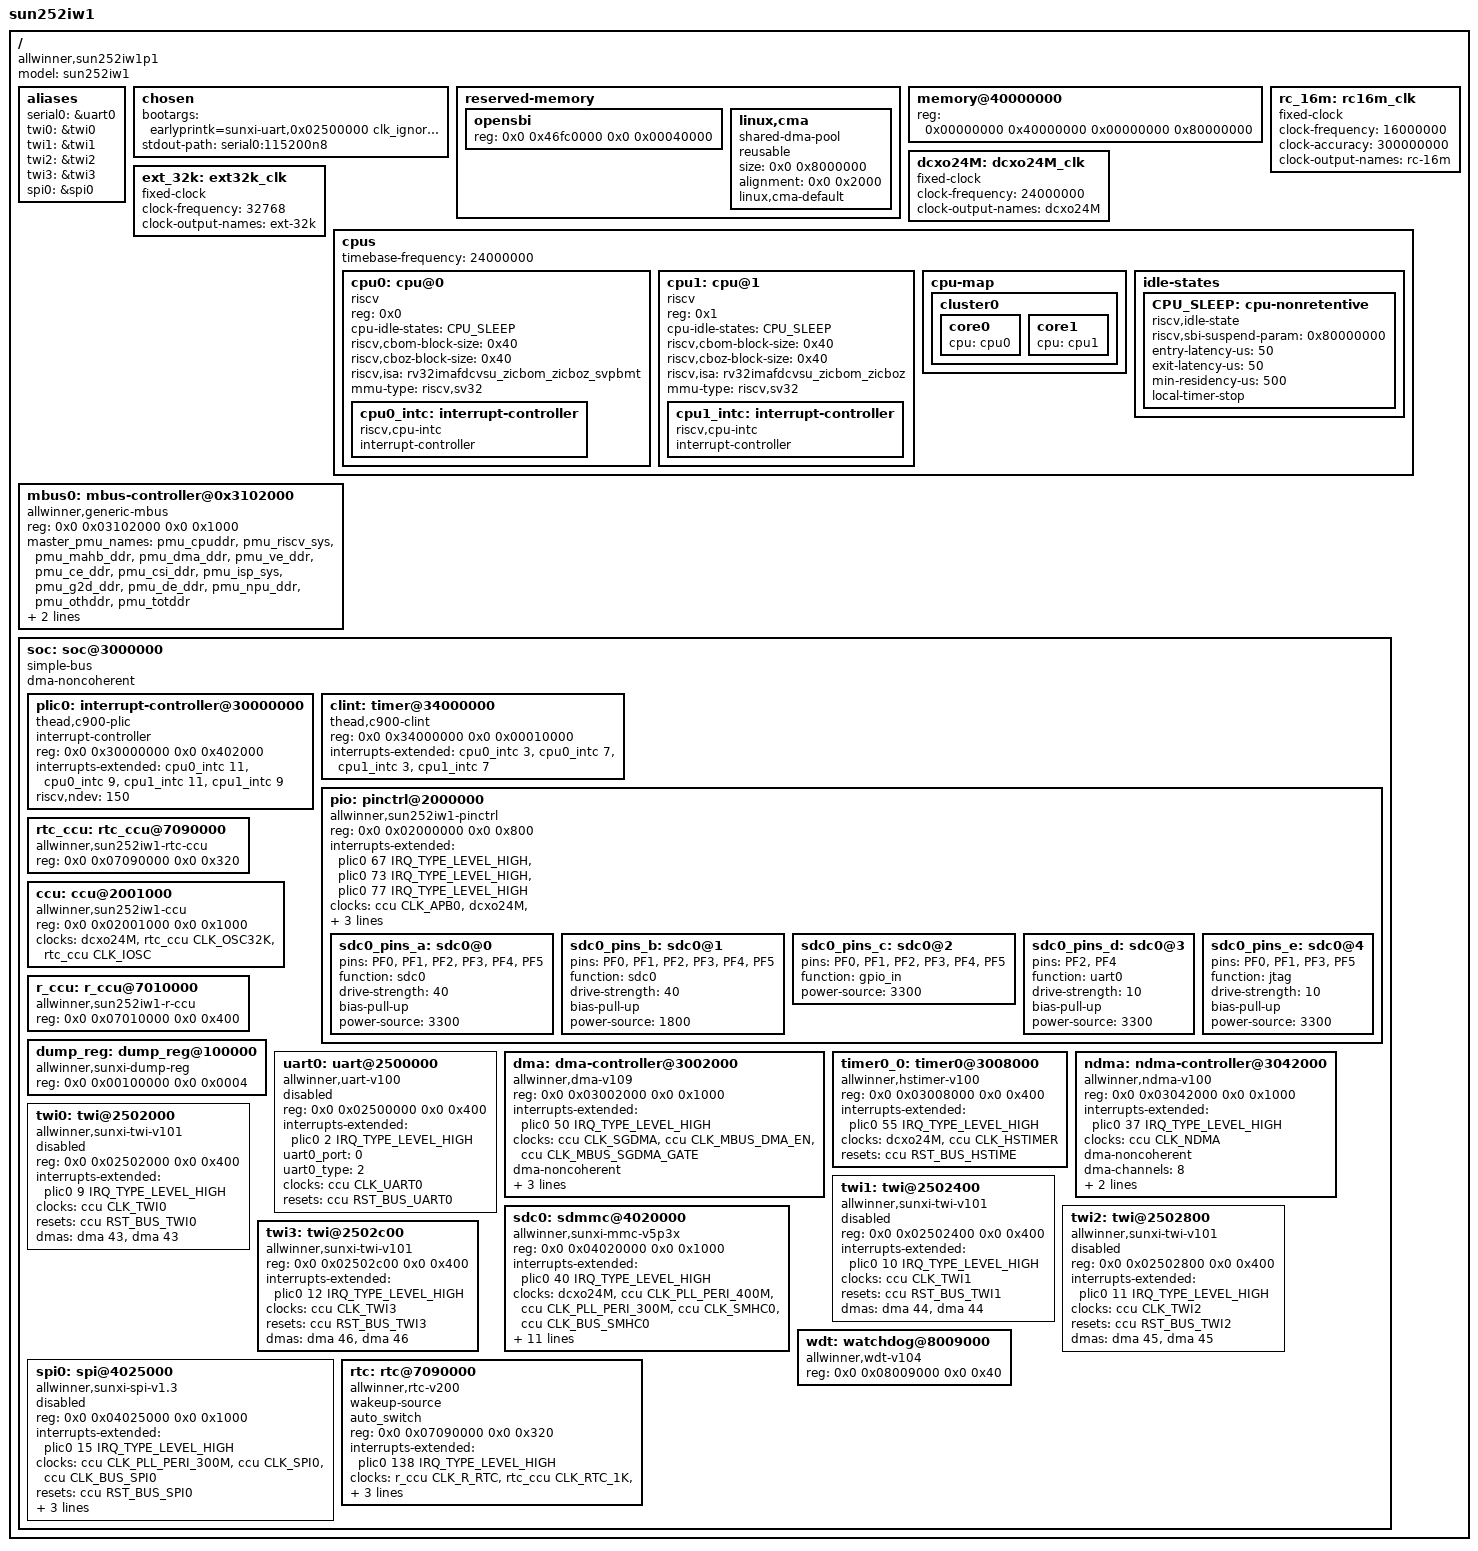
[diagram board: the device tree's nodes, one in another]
// SPDX-License-Identifier: (GPL-2.0+ or MIT)
#include <dt-bindings/clock/sun252iw1-ccu.h>
#include <dt-bindings/clock/sun252iw1-r-ccu.h>
#include <dt-bindings/clock/sun252iw1-rtc.h>
#include <dt-bindings/reset/sun252iw1-ccu.h>
#include <dt-bindings/reset/sun252iw1-r-ccu.h>
#include <dt-bindings/gpio/gpio.h>
#include <dt-bindings/gpio/sun4i-gpio.h>
#include <dt-bindings/interrupt-controller/irq.h>
#include <dt-bindings/phy/phy.h>
#include <dt-bindings/thermal/thermal.h>
#include <dt-bindings/spi/sunxi-spi.h>

/ {
	model = "sun252iw1";
	compatible = "allwinner,sun252iw1p1";
	#address-cells = <2>;
	#size-cells = <2>;

	aliases {
		serial0 = &uart0;
		twi0 = &twi0;
		twi1 = &twi1;
		twi2 = &twi2;
		twi3 = &twi3;
		spi0 = &spi0;
	};

	chosen {
		bootargs = "earlyprintk=sunxi-uart,0x02500000 clk_ignore_unused initcall_debug=0 console=ttyAS0,115200 loglevel=8 root=/dev/mmcblk0p5 init=/init partitions=boot-resource@mmcblk0p1:env@mmcblk0p2:env-redund@mmcblk0p3:boot@mmcblk0p4:rootfs@mmcblk0p5:private@mmcblk0p6:rootfs_data@mmcblk0p7:UDISK@mmcblk0p8 specialstr= gpt=1 mbr_offset=1556480";
		stdout-path = "serial0:115200n8";  /* opensbi needs this */
	};

	reserved-memory {
		#address-cells = <2>;
		#size-cells = <2>;
		ranges;
		opensbi {
			reg = <0x0 0x46fc0000 0x0 0x00040000>;
		};

		linux,cma {
			compatible = "shared-dma-pool";
			reusable;
			size = <0x0 0x8000000>;
			alignment = <0x0 0x2000>;
			linux,cma-default;
		};
	};

	/* avoid panic when memory-node err(from uboot) */
	memory@40000000 {
		device_type = "memory";
		reg = <0x00000000 0x40000000 0x00000000 0x80000000>;
	};

	dcxo24M: dcxo24M_clk {
		#clock-cells = <0>;
		compatible = "fixed-clock";
		clock-frequency = <24000000>;
		clock-output-names = "dcxo24M";
	};

	rc_16m: rc16m_clk {
		#clock-cells = <0>;
		compatible = "fixed-clock";
		clock-frequency = <16000000>;
		clock-accuracy = <300000000>;
		clock-output-names = "rc-16m";
	};

	ext_32k: ext32k_clk {
		#clock-cells = <0>;
		compatible = "fixed-clock";
		clock-frequency = <32768>;
		clock-output-names = "ext-32k";
	};
	cpus {
		#address-cells = <1>;
		#size-cells = <0>;
		timebase-frequency = <24000000>;

		cpu0: cpu@0 {
			device_type = "cpu";
			reg = <0x0>;
			status = "okay";
			compatible = "riscv";
			cpu-idle-states = <&CPU_SLEEP>;
			riscv,cbom-block-size = <0x40>;
			riscv,cboz-block-size = <0x40>;
			riscv,isa = "rv32imafdcvsu_zicbom_zicboz_svpbmt";
			mmu-type = "riscv,sv32";
			cpu0_intc: interrupt-controller {
				#address-cells = <0>;
				#interrupt-cells = <1>;
				compatible = "riscv,cpu-intc";
				interrupt-controller;
			};
		};

		cpu1: cpu@1 {
			device_type = "cpu";
			reg = <0x1>;
			status = "okay";
			compatible = "riscv";
			cpu-idle-states = <&CPU_SLEEP>;
			riscv,cbom-block-size = <0x40>;
			riscv,cboz-block-size = <0x40>;
			riscv,isa = "rv32imafdcvsu_zicbom_zicboz";
			mmu-type = "riscv,sv32";
			cpu1_intc: interrupt-controller {
				#address-cells = <0>;
				#interrupt-cells = <1>;
				compatible = "riscv,cpu-intc";
				interrupt-controller;
			};
		};

		cpu-map {
			cluster0 {
				core0 {
					cpu = <&cpu0>;
				};
				core1 {
					cpu = <&cpu1>;
				};
			};
		};

		idle-states {
			CPU_SLEEP: cpu-nonretentive {
				compatible = "riscv,idle-state";
				riscv,sbi-suspend-param = <0x80000000>;
				entry-latency-us = <50>;
				exit-latency-us = <50>;
				min-residency-us = <500>;
				local-timer-stop;
			};
		};
	};

	mbus0: mbus-controller@0x3102000 {
		compatible = "allwinner,generic-mbus";
		reg = <0x0 0x03102000 0x0 0x1000>;
		#mbus-cells = <1>;
		status = "okay";
		master_pmu_names = "pmu_cpuddr", "pmu_riscv_sys", "pmu_mahb_ddr",
		"pmu_dma_ddr", "pmu_ve_ddr", "pmu_ce_ddr", "pmu_csi_ddr",
		"pmu_isp_sys", "pmu_g2d_ddr", "pmu_de_ddr", "pmu_npu_ddr",
		"pmu_othddr", "pmu_totddr";
		master_pmu_idxs =<0 1 2 3 4 6 7 8 9 10 13 14 15>;
		master_port_idxs = <0 39 2 3 4 40 11 12 13 16 38>;
	};

	soc: soc@3000000 {
		compatible = "simple-bus";
		#address-cells = <2>;
		#size-cells = <2>;
		ranges;
		dma-noncoherent;

		plic0: interrupt-controller@30000000 {
			compatible = "thead,c900-plic";
			#address-cells = <0>;
			#interrupt-cells = <2>;
			interrupt-controller;
			reg = <0x0 0x30000000 0x0 0x402000>;
			interrupts-extended = <&cpu0_intc 11 &cpu0_intc 9>,
					      <&cpu1_intc 11 &cpu1_intc 9>;
			riscv,ndev = <150>;
		};

		clint: timer@34000000 {
			compatible = "thead,c900-clint";
			reg = <0x0 0x34000000 0x0 0x00010000>;
			interrupts-extended = <&cpu0_intc 3>, <&cpu0_intc 7>,
					      <&cpu1_intc 3>, <&cpu1_intc 7>;
		};

		pio: pinctrl@2000000 {
			compatible = "allwinner,sun252iw1-pinctrl";
			reg = <0x0 0x02000000 0x0 0x800>;
			interrupts-extended = <&plic0 67 IRQ_TYPE_LEVEL_HIGH>,
				<&plic0 73 IRQ_TYPE_LEVEL_HIGH>,
				<&plic0 77 IRQ_TYPE_LEVEL_HIGH>;
			clocks = <&ccu CLK_APB0>, <&dcxo24M>, <&rtc_ccu CLK_OSC32K>;
			clock-names = "apb", "hosc", "losc";
			gpio-controller;
			#gpio-cells = <3>;
			interrupt-controller;
			#interrupt-cells = <3>;
			#address-cells = <2>;

			sdc0_pins_a: sdc0@0 {
				pins = "PF0", "PF1", "PF2",
						"PF3", "PF4", "PF5";
				function = "sdc0";
				drive-strength = <40>;
				bias-pull-up;
				power-source = <3300>;
			};

			sdc0_pins_b: sdc0@1 {
				pins = "PF0", "PF1", "PF2",
						"PF3", "PF4", "PF5";
				function = "sdc0";
				drive-strength = <40>;
				bias-pull-up;
				power-source = <1800>;
			};

			sdc0_pins_c: sdc0@2 {
				pins = "PF0", "PF1", "PF2",
						"PF3", "PF4", "PF5";
				function = "gpio_in";
				power-source = <3300>;
			};

			/* TODO: add jtag pin */
			sdc0_pins_d: sdc0@3 {
				pins = "PF2", "PF4";
				function = "uart0";
				drive-strength = <10>;
				bias-pull-up;
				power-source = <3300>;
			};

			sdc0_pins_e: sdc0@4 {
				pins = "PF0", "PF1", "PF3",
						"PF5";
				function = "jtag";
				drive-strength = <10>;
				bias-pull-up;
				power-source = <3300>;
			};
		};

		rtc_ccu: rtc_ccu@7090000 {
			compatible = "allwinner,sun252iw1-rtc-ccu";
			device_type = "rtc-ccu";
			reg = <0x0 0x07090000 0x0 0x320>;  /* The same as rtc */
			#clock-cells = <1>;
		};

		ccu: ccu@2001000 {
			compatible = "allwinner,sun252iw1-ccu";
			reg = <0x0 0x02001000 0x0 0x1000>;
			clocks = <&dcxo24M>, <&rtc_ccu CLK_OSC32K>, <&rtc_ccu CLK_IOSC>;
			clock-names = "hosc", "losc", "iosc";
			#clock-cells = <1>;
			#reset-cells = <1>;
		};

		r_ccu: r_ccu@7010000 {
			compatible = "allwinner,sun252iw1-r-ccu";
			reg = <0x0 0x07010000 0x0 0x400>;
			#clock-cells = <1>;
			#reset-cells = <1>;
		};

		dump_reg:dump_reg@100000 {
			compatible = "allwinner,sunxi-dump-reg";
			reg = <0x0 0x00100000 0x0 0x0004>;
		};

		uart0: uart@2500000 {
			compatible = "allwinner,uart-v100",
				     "allwinner,sunxi-uart";  /* opensbi needs this */
			reg = <0x0 0x02500000 0x0 0x400>;
			interrupts-extended = <&plic0 2 IRQ_TYPE_LEVEL_HIGH>;
			uart0_port = <0>;
			uart0_type = <2>;
			clocks = <&ccu CLK_UART0>;
			resets = <&ccu RST_BUS_UART0>;
			status = "disabled";
		};

		dma:dma-controller@3002000 {
			compatible = "allwinner,dma-v109";
			reg = <0x0 0x03002000 0x0 0x1000>;
			interrupts-extended = <&plic0 50 IRQ_TYPE_LEVEL_HIGH>;
			clocks = <&ccu CLK_SGDMA>, <&ccu CLK_MBUS_DMA_EN>, <&ccu CLK_MBUS_SGDMA_GATE>;
			clock-names = "bus", "mbus-en", "mbus";
			dma-noncoherent;
			dma-channels = <4>;
			dma-requests = <64>;
			resets = <&ccu RST_BUS_SGDMA>;
			#dma-cells = <1>;
			status = "okay";
		};

		timer0_0: timer0@3008000 {
			compatible = "allwinner,hstimer-v100";
			device_type = "timer0";
			reg = <0x0 0x03008000 0x0 0x400>;
			interrupts-extended = <&plic0 55 IRQ_TYPE_LEVEL_HIGH>;
			clocks = <&dcxo24M>, <&ccu CLK_HSTIMER>;
			clock-names = "parent", "bus";
			resets = <&ccu RST_BUS_HSTIME>;
		};

		ndma:ndma-controller@3042000 {
			compatible = "allwinner,ndma-v100";
			reg = <0x0 0x03042000 0x0 0x1000>;
			interrupts-extended = <&plic0 37 IRQ_TYPE_LEVEL_HIGH>;
			clocks = <&ccu CLK_NDMA>;
			clock-names = "bus";
			dma-noncoherent;
			dma-channels = <8>;
			dma-requests = <64>;
			resets = <&ccu RST_BUS_NDMA>;
			#dma-cells = <1>;
			status = "okay";
		};

		sdc0: sdmmc@4020000 {
			compatible = "allwinner,sunxi-mmc-v5p3x";
			device_type = "sdc0";
			reg = <0x0 0x04020000 0x0 0x1000>;
			interrupts-extended = <&plic0 40 IRQ_TYPE_LEVEL_HIGH>;
			clocks = <&dcxo24M>,
				 <&ccu CLK_PLL_PERI_400M>,
				 <&ccu CLK_PLL_PERI_300M>,
				 <&ccu CLK_SMHC0>,
				 <&ccu CLK_BUS_SMHC0>;
			clock-names = "osc24m","pll_periph","pll_periph_2","mmc","ahb";
			resets = <&ccu RST_BUS_SMHC0>;
			reset-names = "rst";
			pinctrl-names = "default","mmc_1v8","sleep","uart_jtag";
			pinctrl-0 = <&sdc0_pins_a>;
			pinctrl-1 = <&sdc0_pins_b>;
			pinctrl-2 = <&sdc0_pins_c>;
			pinctrl-3 = <&sdc0_pins_d &sdc0_pins_e>;
			max-frequency = <50000000>;
			bus-width = <4>;
			req-page-count = <2>;
			/*non-removable;*/
			/*broken-cd;*/
			/*cd-inverted*/
			/*cd-gpios = <&pio PF 6 GPIO_ACTIVE_LOW>;*/
			/* vmmc-supply = <&reg_3p3v>;*/
			/* vqmc-supply = <&reg_3p3v>;*/
			/* vdmc-supply = <&reg_3p3v>;*/
			/*vmmc = "vcc-card";*/
			/*vqmc = "";*/
			/*vdmc = "";*/
			cap-sd-highspeed;
			cap-wait-while-busy;
			/*sd-uhs-sdr50;*/
			/*sd-uhs-ddr50;*/
			/*cap-sdio-irq;*/
			/*keep-power-in-suspend;*/
			/*ignore-pm-notify;*/
			/*sunxi-power-save-mode;*/
			/*sunxi-dly-400k = <1 0 0 0>; */
			/*sunxi-dly-26M  = <1 0 0 0>;*/
			/*sunxi-dly-52M  = <1 0 0 0>;*/
			/*sunxi-dly-52M-ddr4  = <1 0 0 0>;*/
			/*sunxi-dly-52M-ddr8  = <1 0 0 0>;*/
			/*sunxi-dly-104M  = <1 0 0 0>;*/
			/*sunxi-dly-208M  = <1 0 0 0>;*/
			/*sunxi-dly-104M-ddr  = <1 0 0 0>;*/
			/*sunxi-dly-208M-ddr  = <1 0 0 0>;*/
			ctl-spec-caps = <0x428>;
			status = "okay";
		};

		twi0: twi@2502000 {
			#address-cells = <1>;
			#size-cells = <0>;
			compatible = "allwinner,sunxi-twi-v101";
			device_type = "twi0";
			reg = <0x0 0x02502000 0x0 0x400>;
			interrupts-extended= <&plic0 9 IRQ_TYPE_LEVEL_HIGH>;
			clocks = <&ccu CLK_TWI0>;
			resets = <&ccu RST_BUS_TWI0>;
			clock-names = "bus";
			dmas = <&dma 43>, <&dma 43>;
			dma-names = "tx", "rx";
			status = "disabled";
		};

		twi1: twi@2502400 {
			#address-cells = <1>;
			#size-cells = <0>;
			compatible = "allwinner,sunxi-twi-v101";
			device_type = "twi1";
			reg = <0x0 0x02502400 0x0 0x400>;
			interrupts-extended= <&plic0 10 IRQ_TYPE_LEVEL_HIGH>;
			clocks = <&ccu CLK_TWI1>;
			resets = <&ccu RST_BUS_TWI1>;
			clock-names = "bus";
			dmas = <&dma 44>, <&dma 44>;
			dma-names = "tx", "rx";
			status = "disabled";
		};

		twi2: twi@2502800 {
			#address-cells = <1>;
			#size-cells = <0>;
			compatible = "allwinner,sunxi-twi-v101";
			device_type = "twi2";
			reg = <0x0 0x02502800 0x0 0x400>;
			interrupts-extended = <&plic0 11 IRQ_TYPE_LEVEL_HIGH>;
			clocks = <&ccu CLK_TWI2>;
			resets = <&ccu RST_BUS_TWI2>;
			clock-names = "bus";
			dmas = <&dma 45>, <&dma 45>;
			dma-names = "tx", "rx";
			status = "disabled";
		};

		twi3: twi@2502c00 {
			#address-cells = <1>;
			#size-cells = <0>;
			compatible = "allwinner,sunxi-twi-v101";
			device_type = "twi3";
			reg = <0x0 0x02502c00 0x0 0x400>;
			interrupts-extended = <&plic0 12 IRQ_TYPE_LEVEL_HIGH>;
			clocks = <&ccu CLK_TWI3>;
			resets = <&ccu RST_BUS_TWI3>;
			clock-names = "bus";
			dmas = <&dma 46>, <&dma 46>;
			dma-names = "tx", "rx";
		};

		spi0: spi@4025000 {
			#address-cells = <1>;
			#size-cells = <0>;
			compatible = "allwinner,sunxi-spi-v1.3";
			reg = <0x0 0x04025000 0x0 0x1000>;
			interrupts-extended = <&plic0 15 IRQ_TYPE_LEVEL_HIGH>;
			clocks = <&ccu CLK_PLL_PERI_300M>, <&ccu CLK_SPI0>, <&ccu CLK_BUS_SPI0>;
			clock-names = "pll", "mod", "bus";
			resets = <&ccu RST_BUS_SPI0>;
			dmas = <&dma 22>, <&dma 22>;
			dma-names = "tx", "rx";
			clock-frequency = <100000000>;
			sunxi,spi-num-cs = <2>;
			status = "disabled";
		};

		rtc: rtc@7090000 {
			compatible = "allwinner,rtc-v200";
			device_type = "rtc";
			wakeup-source;
			auto_switch;
			reg = <0x0 0x07090000 0x0 0x320>;
			interrupts-extended  = <&plic0 138 IRQ_TYPE_LEVEL_HIGH>;
			clocks = <&r_ccu CLK_R_RTC>, <&rtc_ccu CLK_RTC_1K>, <&rtc_ccu CLK_RTC_SPI>;
			clock-names = "r-ahb-rtc", "rtc-1k", "rtc-spi";
			resets = <&r_ccu RST_BUS_R_RTC>;
			gpr_cur_pos = <6>;
		};

		wdt: watchdog@8009000 {
			compatible = "allwinner,wdt-v104";
			reg = <0x0 0x08009000 0x0 0x40>;
			status = "okay";
		};
	};
};
